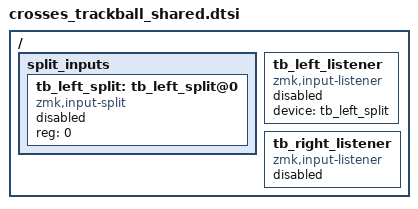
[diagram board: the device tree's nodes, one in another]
/ {
  split_inputs {
    #address-cells = <1>;
    #size-cells = <0>;

    tb_left_split: tb_left_split@0 {
      compatible = "zmk,input-split";
      reg = <0>;
      status = "disabled"; /* Disable until enabled in the overlay */
    };
  };

  tb_left_listener: tb_left_listener {
    compatible = "zmk,input-listener";
    status = "disabled";
    device = <&tb_left_split>;
  };

  tb_right_listener: tb_right_listener {
    compatible = "zmk,input-listener";
    status = "disabled";
  };
};
